# iostm32f105xx register map
Registers are 32-bit, access not given, no defined reset value unless marked. A register's access mark holds for its fields unless they carry their own. Addresses are absolute; registers are grouped by the start of their names; [hi:lo] are bit positions; {n}, {i} and the like mark numbered series.

## IWDG
0x40003000 IWDG_KR 16-bit
0x40003004 IWDG_PR 16-bit
  [2:0] PR
0x40003008 IWDG_RLR 16-bit
  [11:0] RL
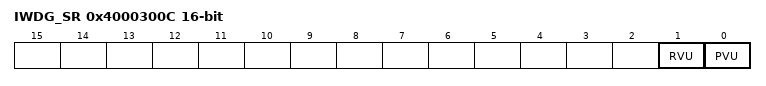
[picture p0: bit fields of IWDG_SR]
0x4000300C IWDG_SR 16-bit
  [1] RVU, [0] PVU

## WWDG
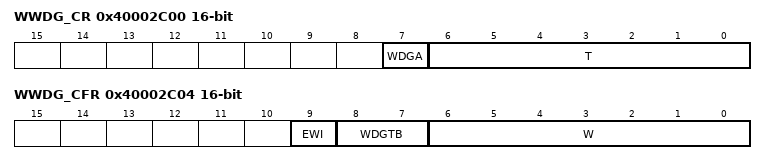
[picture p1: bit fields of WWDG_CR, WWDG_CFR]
0x40002C00 WWDG_CR 16-bit
  [7] WDGA, [6:0] T
0x40002C04 WWDG_CFR 16-bit
  [9] EWI, [8:7] WDGTB, [6:0] W
0x40002C08 WWDG_SR 16-bit
  [0] EWIF

## TIM1
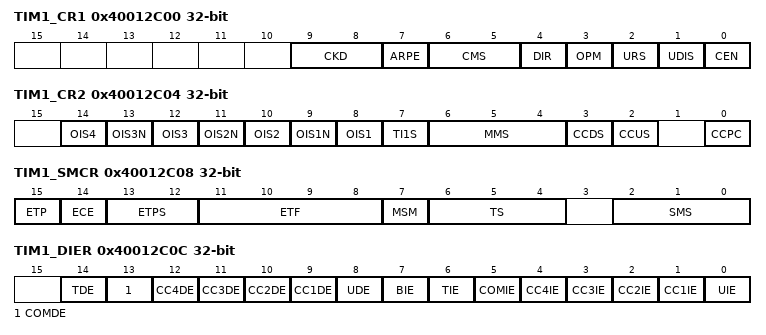
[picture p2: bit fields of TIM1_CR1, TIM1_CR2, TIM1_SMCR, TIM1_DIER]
0x40012C00 TIM1_CR1
  [9:8] CKD, [7] ARPE, [6:5] CMS, [4] DIR, [3] OPM, [2] URS, [1] UDIS, [0] CEN
0x40012C04 TIM1_CR2
  [2n+6] OIS{n} (n=1..4), [13] OIS3N, [11] OIS2N, [9] OIS1N, [7] TI1S, [6:4] MMS, [3] CCDS, [2] CCUS, [0] CCPC
0x40012C08 TIM1_SMCR
  [15] ETP, [14] ECE, [13:12] ETPS, [11:8] ETF, [7] MSM, [6:4] TS, [2:0] SMS
0x40012C0C TIM1_DIER
  [14] TDE, [13] COMDE, [n+8] CC{n}DE (n=1..4), [8] UDE, [7] BIE, [6] TIE, [5] COMIE, [n] CC{n}IE (n=1..4), [0] UIE
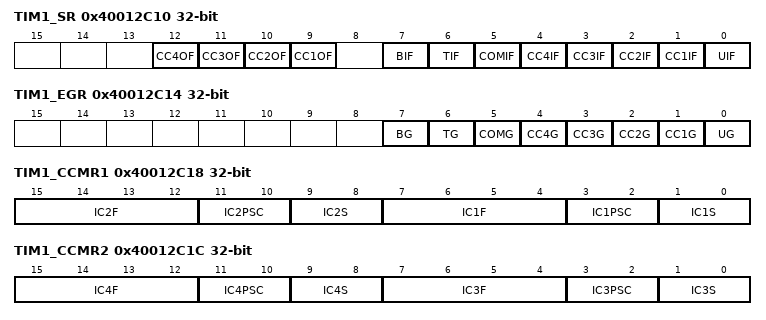
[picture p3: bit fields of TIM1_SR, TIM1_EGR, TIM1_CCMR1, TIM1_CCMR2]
0x40012C10 TIM1_SR
  [n+8] CC{n}OF (n=1..4), [7] BIF, [6] TIF, [5] COMIF, [n] CC{n}IF (n=1..4), [0] UIF
0x40012C14 TIM1_EGR
  [7] BG, [6] TG, [5] COMG, [n] CC{n}G (n=1..4), [0] UG
0x40012C18 TIM1_CCMR1
  [15:12] IC2F, [11:10] IC2PSC, [9:8] IC2S, [7:4] IC1F, [3:2] IC1PSC, [1:0] IC1S
0x40012C18 TIM1_OCMR1
0x40012C1C TIM1_CCMR2
  [15:12] IC4F, [11:10] IC4PSC, [9:8] IC4S, [7:4] IC3F, [3:2] IC3PSC, [1:0] IC3S
0x40012C1C TIM1_OCMR2
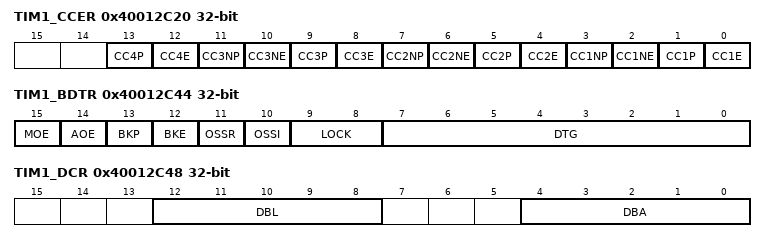
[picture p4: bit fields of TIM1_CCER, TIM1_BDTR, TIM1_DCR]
0x40012C20 TIM1_CCER
  [4n-3] CC{n}P (n=1..4), [4n-4] CC{n}E (n=1..4), [11] CC3NP, [10] CC3NE, [7] CC2NP, [6] CC2NE, [3] CC1NP, [2] CC1NE
0x40012C24 TIM1_CNT
  [15:0] CNT
0x40012C28 TIM1_PSC
  [15:0] PSC
0x40012C2C TIM1_ARR
  [15:0] ARR
0x40012C30 TIM1_RCR
  [7:0] REP
{0x40012C30+4i} TIM1_CCR{i} (i=1..4)
  [15:0] CCR
0x40012C44 TIM1_BDTR
  [15] MOE, [14] AOE, [13] BKP, [12] BKE, [11] OSSR, [10] OSSI, [9:8] LOCK, [7:0] DTG
0x40012C48 TIM1_DCR
  [12:8] DBL, [4:0] DBA
0x40012C4C TIM1_DMAR
  [15:0] DMAB

## TIM2
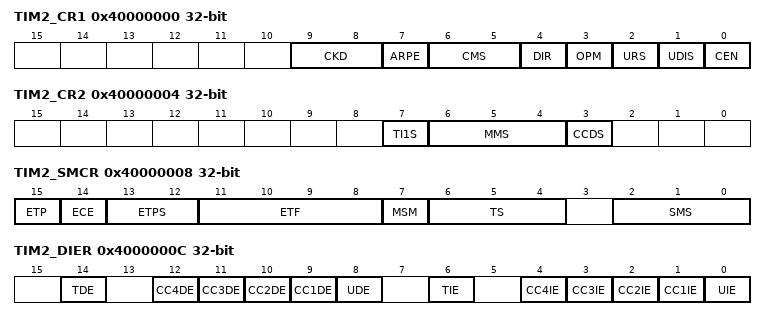
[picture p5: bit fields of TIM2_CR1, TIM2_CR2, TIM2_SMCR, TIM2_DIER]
0x40000000 TIM2_CR1
  [9:8] CKD, [7] ARPE, [6:5] CMS, [4] DIR, [3] OPM, [2] URS, [1] UDIS, [0] CEN
0x40000004 TIM2_CR2
  [7] TI1S, [6:4] MMS, [3] CCDS
0x40000008 TIM2_SMCR
  [15] ETP, [14] ECE, [13:12] ETPS, [11:8] ETF, [7] MSM, [6:4] TS, [2:0] SMS
0x4000000C TIM2_DIER
  [14] TDE, [n+8] CC{n}DE (n=1..4), [8] UDE, [6] TIE, [n] CC{n}IE (n=1..4), [0] UIE
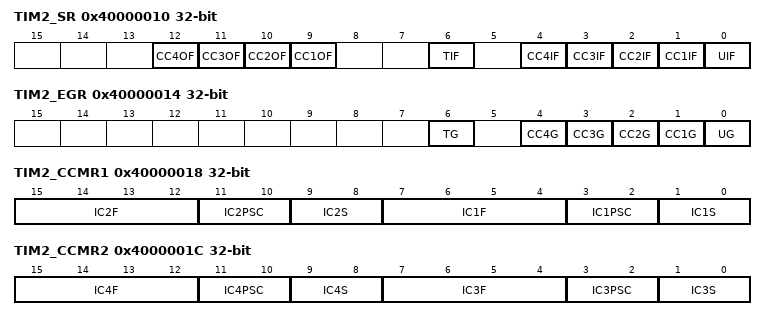
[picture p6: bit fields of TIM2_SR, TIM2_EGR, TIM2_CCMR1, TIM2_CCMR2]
0x40000010 TIM2_SR
  [n+8] CC{n}OF (n=1..4), [6] TIF, [n] CC{n}IF (n=1..4), [0] UIF
0x40000014 TIM2_EGR
  [6] TG, [n] CC{n}G (n=1..4), [0] UG
0x40000018 TIM2_CCMR1
  [15:12] IC2F, [11:10] IC2PSC, [9:8] IC2S, [7:4] IC1F, [3:2] IC1PSC, [1:0] IC1S
0x40000018 TIM2_OCMR1
0x4000001C TIM2_CCMR2
  [15:12] IC4F, [11:10] IC4PSC, [9:8] IC4S, [7:4] IC3F, [3:2] IC3PSC, [1:0] IC3S
0x4000001C TIM2_OCMR2
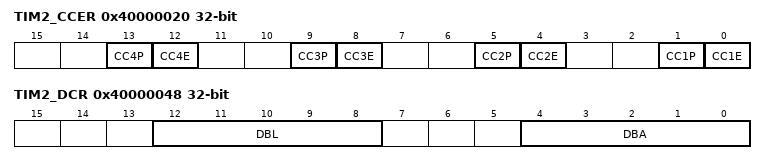
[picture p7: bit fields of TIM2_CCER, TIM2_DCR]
0x40000020 TIM2_CCER
  [4n-3] CC{n}P (n=1..4), [4n-4] CC{n}E (n=1..4)
0x40000024 TIM2_CNT
  [15:0] CNT
0x40000028 TIM2_PSC
  [15:0] PSC
0x4000002C TIM2_ARR
  [15:0] ARR
{0x40000030+4i} TIM2_CCR{i} (i=1..4)
  [15:0] CCR
0x40000048 TIM2_DCR
  [12:8] DBL, [4:0] DBA
0x4000004C TIM2_DMAR
  [15:0] DMAB

## TIM3
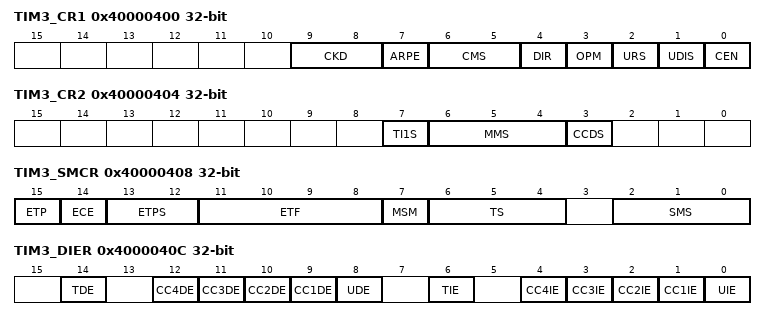
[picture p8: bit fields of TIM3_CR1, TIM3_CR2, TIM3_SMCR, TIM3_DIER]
0x40000400 TIM3_CR1
  [9:8] CKD, [7] ARPE, [6:5] CMS, [4] DIR, [3] OPM, [2] URS, [1] UDIS, [0] CEN
0x40000404 TIM3_CR2
  [7] TI1S, [6:4] MMS, [3] CCDS
0x40000408 TIM3_SMCR
  [15] ETP, [14] ECE, [13:12] ETPS, [11:8] ETF, [7] MSM, [6:4] TS, [2:0] SMS
0x4000040C TIM3_DIER
  [14] TDE, [n+8] CC{n}DE (n=1..4), [8] UDE, [6] TIE, [n] CC{n}IE (n=1..4), [0] UIE
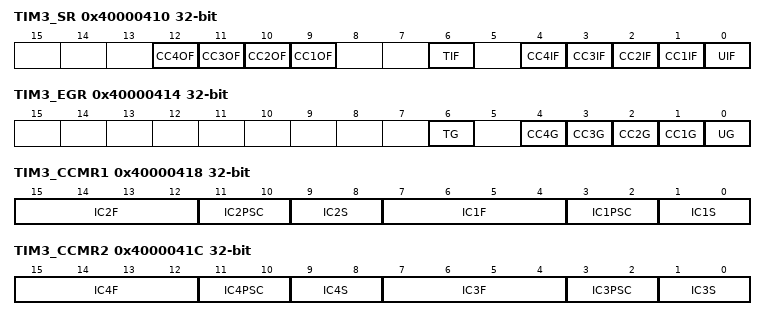
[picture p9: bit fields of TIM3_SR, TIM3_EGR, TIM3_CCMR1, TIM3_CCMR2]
0x40000410 TIM3_SR
  [n+8] CC{n}OF (n=1..4), [6] TIF, [n] CC{n}IF (n=1..4), [0] UIF
0x40000414 TIM3_EGR
  [6] TG, [n] CC{n}G (n=1..4), [0] UG
0x40000418 TIM3_CCMR1
  [15:12] IC2F, [11:10] IC2PSC, [9:8] IC2S, [7:4] IC1F, [3:2] IC1PSC, [1:0] IC1S
0x40000418 TIM3_OCMR1
0x4000041C TIM3_CCMR2
  [15:12] IC4F, [11:10] IC4PSC, [9:8] IC4S, [7:4] IC3F, [3:2] IC3PSC, [1:0] IC3S
0x4000041C TIM3_OCMR2
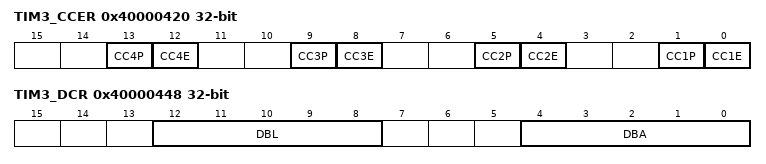
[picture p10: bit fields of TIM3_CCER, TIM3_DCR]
0x40000420 TIM3_CCER
  [4n-3] CC{n}P (n=1..4), [4n-4] CC{n}E (n=1..4)
0x40000424 TIM3_CNT
  [15:0] CNT
0x40000428 TIM3_PSC
  [15:0] PSC
0x4000042C TIM3_ARR
  [15:0] ARR
{0x40000430+4i} TIM3_CCR{i} (i=1..4)
  [15:0] CCR
0x40000448 TIM3_DCR
  [12:8] DBL, [4:0] DBA
0x4000044C TIM3_DMAR
  [15:0] DMAB
